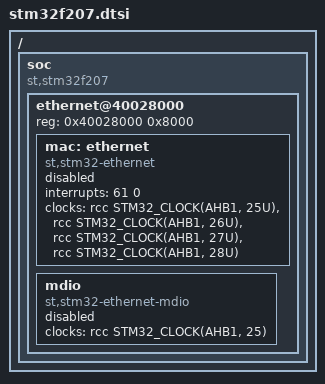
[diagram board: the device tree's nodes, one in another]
/*
 * Copyright (c) 2018 qianfan Zhao
 *
 * SPDX-License-Identifier: Apache-2.0
 */

#include <st/f2/stm32f2.dtsi>

/ {
	soc {
		compatible = "st,stm32f207", "st,stm32f2", "simple-bus";

		ethernet@40028000 {
			reg = <0x40028000 0x8000>;

			mac: ethernet {
				compatible = "st,stm32-ethernet";
				interrupts = <61 0>;
				clock-names = "stmmaceth", "mac-clk-tx",
					      "mac-clk-rx", "mac-clk-ptp";
				clocks = <&rcc STM32_CLOCK(AHB1, 25U)>,
					 <&rcc STM32_CLOCK(AHB1, 26U)>,
					 <&rcc STM32_CLOCK(AHB1, 27U)>,
					 <&rcc STM32_CLOCK(AHB1, 28U)>;
				status = "disabled";
			};

			mdio: mdio {
				compatible = "st,stm32-ethernet-mdio";
				#address-cells = <1>;
				#size-cells = <0>;
				clocks = <&rcc STM32_CLOCK(AHB1, 25)>;
				clock-names = "stmaceth";
				status = "disabled";
			};
		};
	};
};
